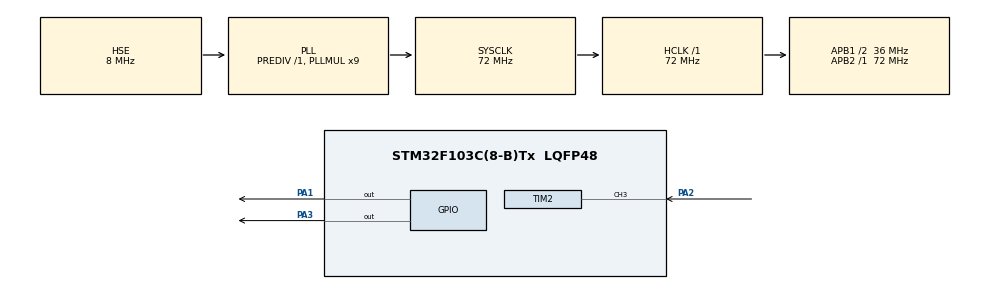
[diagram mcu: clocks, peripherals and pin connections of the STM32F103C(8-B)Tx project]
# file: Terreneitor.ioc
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Mcu.Family=STM32F1
Mcu.Name=STM32F103C(8-B)Tx
Mcu.Package=LQFP48
NVIC.PriorityGroup=NVIC_PRIORITYGROUP_4
NVIC.TIM2_IRQn=true\:0\:0\:false\:false\:true\:true\:true\:true
NVIC.TIM3_IRQn=true\:0\:0\:false\:false\:true\:true\:true\:true
PA1.Signal=GPIO_Output
PA13.Mode=Serial_Wire
PA13.Signal=SYS_JTMS-SWDIO
PA14.Mode=Serial_Wire
PA14.Signal=SYS_JTCK-SWCLK
PA2.Signal=S_TIM2_CH3
PA3.Signal=GPIO_Output
PD0-OSC_IN.Mode=HSE-External-Oscillator
PD0-OSC_IN.Signal=RCC_OSC_IN
PD1-OSC_OUT.Mode=HSE-External-Oscillator
PD1-OSC_OUT.Signal=RCC_OSC_OUT
ProjectManager.HeapSize=0x200
ProjectManager.StackSize=0x400
ProjectManager.TargetToolchain=STM32CubeIDE
RCC.AHBFreq_Value=72000000
RCC.APB1CLKDivider=RCC_HCLK_DIV2
RCC.APB1Freq_Value=36000000
RCC.APB1TimFreq_Value=72000000
RCC.APB2Freq_Value=72000000
RCC.APB2TimFreq_Value=72000000
RCC.HCLKFreq_Value=72000000
RCC.PLLMUL=RCC_PLL_MUL9
RCC.PLLSourceVirtual=RCC_PLLSOURCE_HSE
RCC.SYSCLKFreq_VALUE=72000000
RCC.SYSCLKSource=RCC_SYSCLKSOURCE_PLLCLK
RCC.USBFreq_Value=72000000
SH.S_TIM2_CH3.0=TIM2_CH3,Input_Capture3_from_TI3
TIM2.AutoReloadPreload=TIM_AUTORELOAD_PRELOAD_ENABLE
TIM2.Channel-Input_Capture3_from_TI3=TIM_CHANNEL_3
TIM3.AutoReloadPreload=TIM_AUTORELOAD_PRELOAD_ENABLE
TIM3.Period=7199
TIM3.Prescaler=9
VP_TIM2_VS_ClockSourceINT.Mode=Internal
VP_TIM3_VS_ClockSourceINT.Mode=Internal
board=custom

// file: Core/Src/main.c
/* USER CODE BEGIN Header */
/**
  ******************************************************************************
  * @file           : main.c
  * @brief          : Main program body
  ******************************************************************************
  * @attention
  *
  * Copyright (c) 2024 STMicroelectronics.
  * All rights reserved.
  *
  * This software is licensed under terms that can be found in the LICENSE file
  * in the root directory of this software component.
  * If no LICENSE file comes with this software, it is provided AS-IS.
  *
  ******************************************************************************
  */
/* USER CODE END Header */
#include "main.h"

/* USER CODE BEGIN Includes */
//#include "../../ECUAL/HCSR04/HCSR04.c"
#include "util/DWT_Delay.h"
/* Autor:
 * -Felix Federico Moya
 * Sistemas Embebidos
 *
 * Proyecto:
 * -Es un vehículo manejado por control remoto.
 * -Tiene un sensor ultrasónico para emular los sensores de los carros reales para estacionarse.
 * -Cuenta con una conexión bluetooh para enviar y recibir datos.
 * -Una pantalla LCD para hacer display de la distancia que tienes para estacionar.
 * Convención adoptada para el código:
 * -Constantes van en mayúsculas: int ESTO_ES_UNA_CONSTANTE
 * -Variables con camelCase: int estoEsUnaVariable
 * -Funciones con uppercamelcase: void EstoEsUnaFuncion();
 * -Se utiliza el inglés para el código.
 * Postura Adoptada para la creación de funciones que controlen los componentes externos al microcontrolador:
 * -Las definiciones de los pines, y configuraciones necesarias(del microcontrolador)
 * para el funcionamiento de los componentes se harán a través del STM32CubeIDE.
 * -Esto nos quita portabilidad de archivos, pero nos ahorra en tiempo de desarrollo.
 * -Tampoco se buscará la mayor optimización de la memoria ya que el proyecto no ocupa mucho espacio en memoria.
 */
/* USER CODE END Includes */

/* USER CODE BEGIN PM */
#define TRUE 1
#define FALSE 0
uint16_t SysTicks = 0;
float distance;
uint16_t overFlow;
int EDGE_STATE;
uint32_t TS1; //TimeStamp
float difference;
uint32_t TS2; //TimeStamp
/* USER CODE END PM */

TIM_HandleTypeDef htim2;
TIM_HandleTypeDef htim3;

void SystemClock_Config(void);
static void MX_GPIO_Init(void);
static void MX_TIM2_Init(void);
static void MX_TIM3_Init(void);

int main(void)
{

  /* MCU Configuration--------------------------------------------------------*/

  /* Reset of all peripherals, Initializes the Flash interface and the Systick. */
  HAL_Init();

  /* Configure the system clock */
  SystemClock_Config();

  /* Initialize all configured peripherals */
  MX_GPIO_Init();
  MX_TIM2_Init();
  MX_TIM3_Init();
  /* USER CODE BEGIN 2 */
  DWT_Delay_Init();
  HAL_TIM_Base_Start_IT(&htim2);
  HAL_TIM_Base_Start_IT(&htim3);
  HAL_TIM_IC_Start_IT(&htim2, TIM_CHANNEL_3);
  //HCSR04_Init(&htim2, GPIOA, GPIO_PIN_3, TIM_CHANNEL_3, 72);

  /* USER CODE END 2 */

  /* Infinite loop */
  /* USER CODE BEGIN WHILE */
  while (1)
  {

	if(distance >= 5){
		HAL_GPIO_WritePin(GPIOA, GPIO_PIN_1, 1);
	}
	else{
		HAL_GPIO_WritePin(GPIOA, GPIO_PIN_1, 0);
	}
    /* USER CODE END WHILE */

  }
}

void SystemClock_Config(void)
{
  RCC_OscInitTypeDef RCC_OscInitStruct = {0};
  RCC_ClkInitTypeDef RCC_ClkInitStruct = {0};

  /** Initializes the RCC Oscillators according to the specified parameters
  * in the RCC_OscInitTypeDef structure.
  */
  RCC_OscInitStruct.OscillatorType = RCC_OSCILLATORTYPE_HSE;
  RCC_OscInitStruct.HSEState = RCC_HSE_ON;
  RCC_OscInitStruct.HSEPredivValue = RCC_HSE_PREDIV_DIV1;
  RCC_OscInitStruct.HSIState = RCC_HSI_ON;
  RCC_OscInitStruct.PLL.PLLState = RCC_PLL_ON;
  RCC_OscInitStruct.PLL.PLLSource = RCC_PLLSOURCE_HSE;
  RCC_OscInitStruct.PLL.PLLMUL = RCC_PLL_MUL9;
  if (HAL_RCC_OscConfig(&RCC_OscInitStruct) != HAL_OK)
  {
    Error_Handler();
  }

  /** Initializes the CPU, AHB and APB buses clocks
  */
  RCC_ClkInitStruct.ClockType = RCC_CLOCKTYPE_HCLK|RCC_CLOCKTYPE_SYSCLK
                              |RCC_CLOCKTYPE_PCLK1|RCC_CLOCKTYPE_PCLK2;
  RCC_ClkInitStruct.SYSCLKSource = RCC_SYSCLKSOURCE_PLLCLK;
  RCC_ClkInitStruct.AHBCLKDivider = RCC_SYSCLK_DIV1;
  RCC_ClkInitStruct.APB1CLKDivider = RCC_HCLK_DIV2;
  RCC_ClkInitStruct.APB2CLKDivider = RCC_HCLK_DIV1;

  if (HAL_RCC_ClockConfig(&RCC_ClkInitStruct, FLASH_LATENCY_2) != HAL_OK)
  {
    Error_Handler();
  }
}

static void MX_TIM2_Init(void)
{

  TIM_ClockConfigTypeDef sClockSourceConfig = {0};
  TIM_MasterConfigTypeDef sMasterConfig = {0};
  TIM_IC_InitTypeDef sConfigIC = {0};

  htim2.Instance = TIM2;
  htim2.Init.Prescaler = 0;
  htim2.Init.CounterMode = TIM_COUNTERMODE_UP;
  htim2.Init.Period = 65535;
  htim2.Init.ClockDivision = TIM_CLOCKDIVISION_DIV1;
  htim2.Init.AutoReloadPreload = TIM_AUTORELOAD_PRELOAD_ENABLE;
  if (HAL_TIM_Base_Init(&htim2) != HAL_OK)
  {
    Error_Handler();
  }
  sClockSourceConfig.ClockSource = TIM_CLOCKSOURCE_INTERNAL;
  if (HAL_TIM_ConfigClockSource(&htim2, &sClockSourceConfig) != HAL_OK)
  {
    Error_Handler();
  }
  if (HAL_TIM_IC_Init(&htim2) != HAL_OK)
  {
    Error_Handler();
  }
  sMasterConfig.MasterOutputTrigger = TIM_TRGO_RESET;
  sMasterConfig.MasterSlaveMode = TIM_MASTERSLAVEMODE_DISABLE;
  if (HAL_TIMEx_MasterConfigSynchronization(&htim2, &sMasterConfig) != HAL_OK)
  {
    Error_Handler();
  }
  sConfigIC.ICPolarity = TIM_INPUTCHANNELPOLARITY_RISING;
  sConfigIC.ICSelection = TIM_ICSELECTION_DIRECTTI;
  sConfigIC.ICPrescaler = TIM_ICPSC_DIV1;
  sConfigIC.ICFilter = 0;
  if (HAL_TIM_IC_ConfigChannel(&htim2, &sConfigIC, TIM_CHANNEL_3) != HAL_OK)
  {
    Error_Handler();
  }

}

static void MX_TIM3_Init(void)
{

  TIM_ClockConfigTypeDef sClockSourceConfig = {0};
  TIM_MasterConfigTypeDef sMasterConfig = {0};

  htim3.Instance = TIM3;
  htim3.Init.Prescaler = 9;
  htim3.Init.CounterMode = TIM_COUNTERMODE_UP;
  htim3.Init.Period = 7199;
  htim3.Init.ClockDivision = TIM_CLOCKDIVISION_DIV1;
  htim3.Init.AutoReloadPreload = TIM_AUTORELOAD_PRELOAD_ENABLE;
  if (HAL_TIM_Base_Init(&htim3) != HAL_OK)
  {
    Error_Handler();
  }
  sClockSourceConfig.ClockSource = TIM_CLOCKSOURCE_INTERNAL;
  if (HAL_TIM_ConfigClockSource(&htim3, &sClockSourceConfig) != HAL_OK)
  {
    Error_Handler();
  }
  sMasterConfig.MasterOutputTrigger = TIM_TRGO_RESET;
  sMasterConfig.MasterSlaveMode = TIM_MASTERSLAVEMODE_DISABLE;
  if (HAL_TIMEx_MasterConfigSynchronization(&htim3, &sMasterConfig) != HAL_OK)
  {
    Error_Handler();
  }

}

static void MX_GPIO_Init(void)
{
  GPIO_InitTypeDef GPIO_InitStruct = {0};

  /* GPIO Ports Clock Enable */
  __HAL_RCC_GPIOD_CLK_ENABLE();
  __HAL_RCC_GPIOA_CLK_ENABLE();

  /*Configure GPIO pin Output Level */
  HAL_GPIO_WritePin(GPIOA, GPIO_PIN_1|GPIO_PIN_3, GPIO_PIN_RESET);

  /*Configure GPIO pins : PA1 PA3 */
  GPIO_InitStruct.Pin = GPIO_PIN_1|GPIO_PIN_3;
  GPIO_InitStruct.Mode = GPIO_MODE_OUTPUT_PP;
  GPIO_InitStruct.Pull = GPIO_NOPULL;
  GPIO_InitStruct.Speed = GPIO_SPEED_FREQ_LOW;
  HAL_GPIO_Init(GPIOA, &GPIO_InitStruct);

}

/* USER CODE BEGIN 4 */
void HAL_TIM_PeriodElapsedCallback(TIM_HandleTypeDef* htim)
{

	   if(htim->Instance == TIM3){
		   SysTicks++;
		   if(SysTicks == 15){
			   HAL_GPIO_WritePin(GPIOA, GPIO_PIN_3, 1);
			   DWT_Delay_us(2);
			   HAL_GPIO_WritePin(GPIOA, GPIO_PIN_3, 0);
		       //HCSR04_Trigger();
		       SysTicks = 0;
		   }
	   }
	   else if(htim->Instance == TIM2){
		   //HCSR04_TMR_OVF_ISR();
		   overFlow++;
	   }
}

void HAL_TIM_IC_CaptureCallback(TIM_HandleTypeDef *htim){
	  //HCSR04_IC_ISR(htim);
	uint32_t PS = 0;
		if(EDGE_STATE == 0){
			//Obtenemos el TS1
			TS1 = HAL_TIM_ReadCapturedValue(htim, TIM_CHANNEL_3);
			//Cambiamos la polaridad del IC
			EDGE_STATE = 1;
			__HAL_TIM_SET_CAPTUREPOLARITY(htim, TIM_CHANNEL_3, TIM_INPUTCHANNELPOLARITY_FALLING);
			//Seteamos Overflow a 0, esto nos ayuda a contar cuantos OVF tuvimos para luego calcular TS2
			overFlow = 0;
		}
		else{
			PS = htim->Instance->PSC;
			//Obtemos el TS2
			TS2 = HAL_TIM_ReadCapturedValue(htim, TIM_CHANNEL_3);
			TS2 += (overFlow * (htim->Instance->ARR + 1));
			difference = TS2 - TS1;
			//Calculamos la Distancia
			distance = (difference * 0.017)/(72/(PS+1));
			//Cambiamos la polaridad del IC preparándolo para la captura de una nueva onda
			EDGE_STATE = 0;
			__HAL_TIM_SET_CAPTUREPOLARITY(htim, TIM_CHANNEL_3, TIM_INPUTCHANNELPOLARITY_RISING);
		}
}
/* USER CODE END 4 */

void Error_Handler(void)
{
  __disable_irq();
  while (1)
  {
  }
}
